# OTPW register map
Registers from a debugger description file.
Registers are 32-bit, read-only, no defined reset value unless marked. A register's access mark holds for its fields unless they carry their own. Addresses are absolute; registers are grouped by the start of their names; lines under a group give offsets from that group; [hi:lo] are bit positions; {n}, {i} and the like mark numbered series; 'fields as' and 'values as' point back to an identical list; <NAME> marks a mode.

## SFR
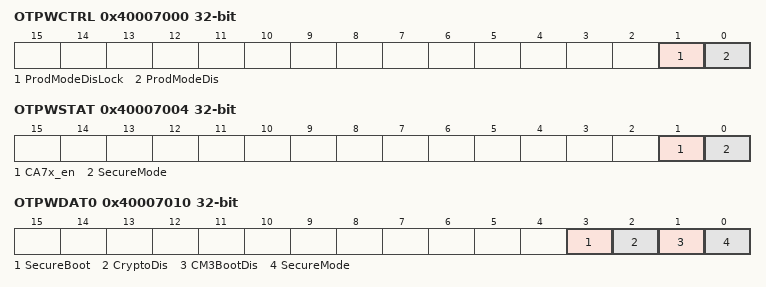
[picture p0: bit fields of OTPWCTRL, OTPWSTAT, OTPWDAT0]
0x40007000 OTPWCTRL access not given
  [1] ProdModeDisLock, [0] ProdModeDis
0x40007004 OTPWSTAT
  [1] CA7x_en, [0] SecureMode
0x40007008 OTPWCHIPID0
0x4000700C OTPWCHIPID1
0x40007010 OTPWDAT0
  [3] SecureBoot, [2] CryptoDis, [1] CM3BootDis, [0] SecureMode
{0x40007010+4i} OTPWDAT{i} (i=1..8)
